VERSION ""

NS_ :

BS_:

BU_: Vector__XXX

BA_DEF_ "BusType" STRING ;
BA_DEF_ BO_ "VFrameFormat" ENUM "StandardCAN","ExtendedCAN","reserved","J1939PG";
BA_DEF_ BO_ "GenMsgCycleTime" INT 0 60000;
BA_DEF_DEF_ "BusType" "CAN";
BA_DEF_DEF_ "VFrameFormat" 0;
BA_DEF_DEF_ "GenMsgCycleTime" 0;

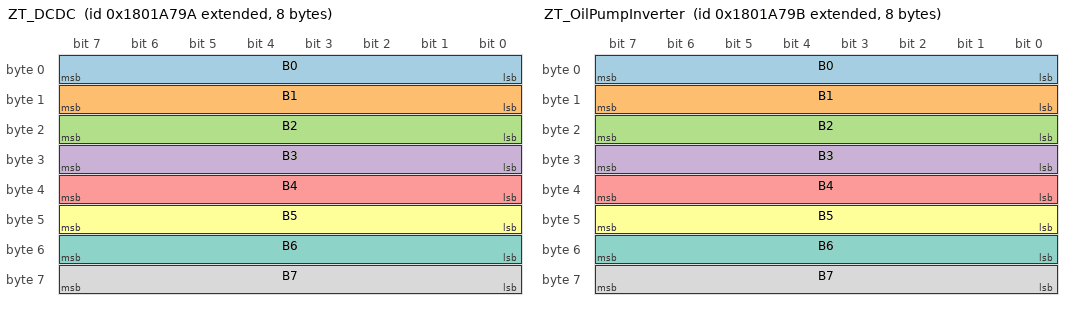
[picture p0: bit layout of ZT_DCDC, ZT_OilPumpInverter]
BO_ 2550245274 ZT_DCDC: 8 Vector__XXX
 SG_ B0 : 0|8@1+ (1,0) [0|255] "" Vector__XXX
 SG_ B1 : 8|8@1+ (1,0) [0|255] "" Vector__XXX
 SG_ B2 : 16|8@1+ (1,0) [0|255] "" Vector__XXX
 SG_ B3 : 24|8@1+ (1,0) [0|255] "" Vector__XXX
 SG_ B4 : 32|8@1+ (1,0) [0|255] "" Vector__XXX
 SG_ B5 : 40|8@1+ (1,0) [0|255] "" Vector__XXX
 SG_ B6 : 48|8@1+ (1,0) [0|255] "" Vector__XXX
 SG_ B7 : 56|8@1+ (1,0) [0|255] "" Vector__XXX
BA_ "VFrameFormat" BO_ 2550245274 1;
BA_ "GenMsgCycleTime" BO_ 2550245274 10000;
CM_ BO_ 2550245274 "中文: 中通 DCDC 直流变压器 / English: Zhongtong DCDC converter | idm 0xB3000006, 配置 HD_ZHONGTONGDEV/DataSteam_Option.txt | 监听 ID 1801A79A;1801A89A (多车型共用) | 实测 325s 恒定: 00 00 01 00 00 3B 09 00 | 本地缺该版信号定义, 按字节 B0-B7 输出, 换算系数待确认";

BO_ 2550245275 ZT_OilPumpInverter: 8 Vector__XXX
 SG_ B0 : 0|8@1+ (1,0) [0|255] "" Vector__XXX
 SG_ B1 : 8|8@1+ (1,0) [0|255] "" Vector__XXX
 SG_ B2 : 16|8@1+ (1,0) [0|255] "" Vector__XXX
 SG_ B3 : 24|8@1+ (1,0) [0|255] "" Vector__XXX
 SG_ B4 : 32|8@1+ (1,0) [0|255] "" Vector__XXX
 SG_ B5 : 40|8@1+ (1,0) [0|255] "" Vector__XXX
 SG_ B6 : 48|8@1+ (1,0) [0|255] "" Vector__XXX
 SG_ B7 : 56|8@1+ (1,0) [0|255] "" Vector__XXX
BA_ "VFrameFormat" BO_ 2550245275 1;
BA_ "GenMsgCycleTime" BO_ 2550245275 1000;
CM_ BO_ 2550245275 "中文: 中通 油泵 DC-AC 逆变器 / English: Zhongtong oil-pump inverter | idm 0xB3000009, 配置 HD_ZHONGTONGDEV/DataSteam_Option.txt | 监听 ID 1801A79B;1811A79B;1821A79B;1831A79B | 实测 325s 恒定: 00 00 00 00 00 00 3D 01 | 本地缺该版信号定义, 按字节 B0-B7 输出, 换算系数待确认";

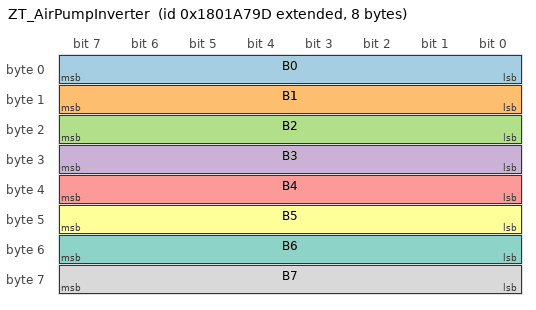
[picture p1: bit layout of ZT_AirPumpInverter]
BO_ 2550245277 ZT_AirPumpInverter: 8 Vector__XXX
 SG_ B0 : 0|8@1+ (1,0) [0|255] "" Vector__XXX
 SG_ B1 : 8|8@1+ (1,0) [0|255] "" Vector__XXX
 SG_ B2 : 16|8@1+ (1,0) [0|255] "" Vector__XXX
 SG_ B3 : 24|8@1+ (1,0) [0|255] "" Vector__XXX
 SG_ B4 : 32|8@1+ (1,0) [0|255] "" Vector__XXX
 SG_ B5 : 40|8@1+ (1,0) [0|255] "" Vector__XXX
 SG_ B6 : 48|8@1+ (1,0) [0|255] "" Vector__XXX
 SG_ B7 : 56|8@1+ (1,0) [0|255] "" Vector__XXX
BA_ "VFrameFormat" BO_ 2550245277 1;
BA_ "GenMsgCycleTime" BO_ 2550245277 1000;
CM_ BO_ 2550245277 "中文: 中通 气泵 DC-AC 逆变器 / English: Zhongtong air-pump inverter | idm 0xB3000008, 配置 HD_ZHONGTONGDEV/DataSteam_Option.txt | 监听 ID 1801A79D;1811A79D;1821A79D;1831A79D | 实测 325s 恒定: 00 00 00 00 00 00 3D 08 | 本地缺该版信号定义, 按字节 B0-B7 输出, 换算系数待确认";
